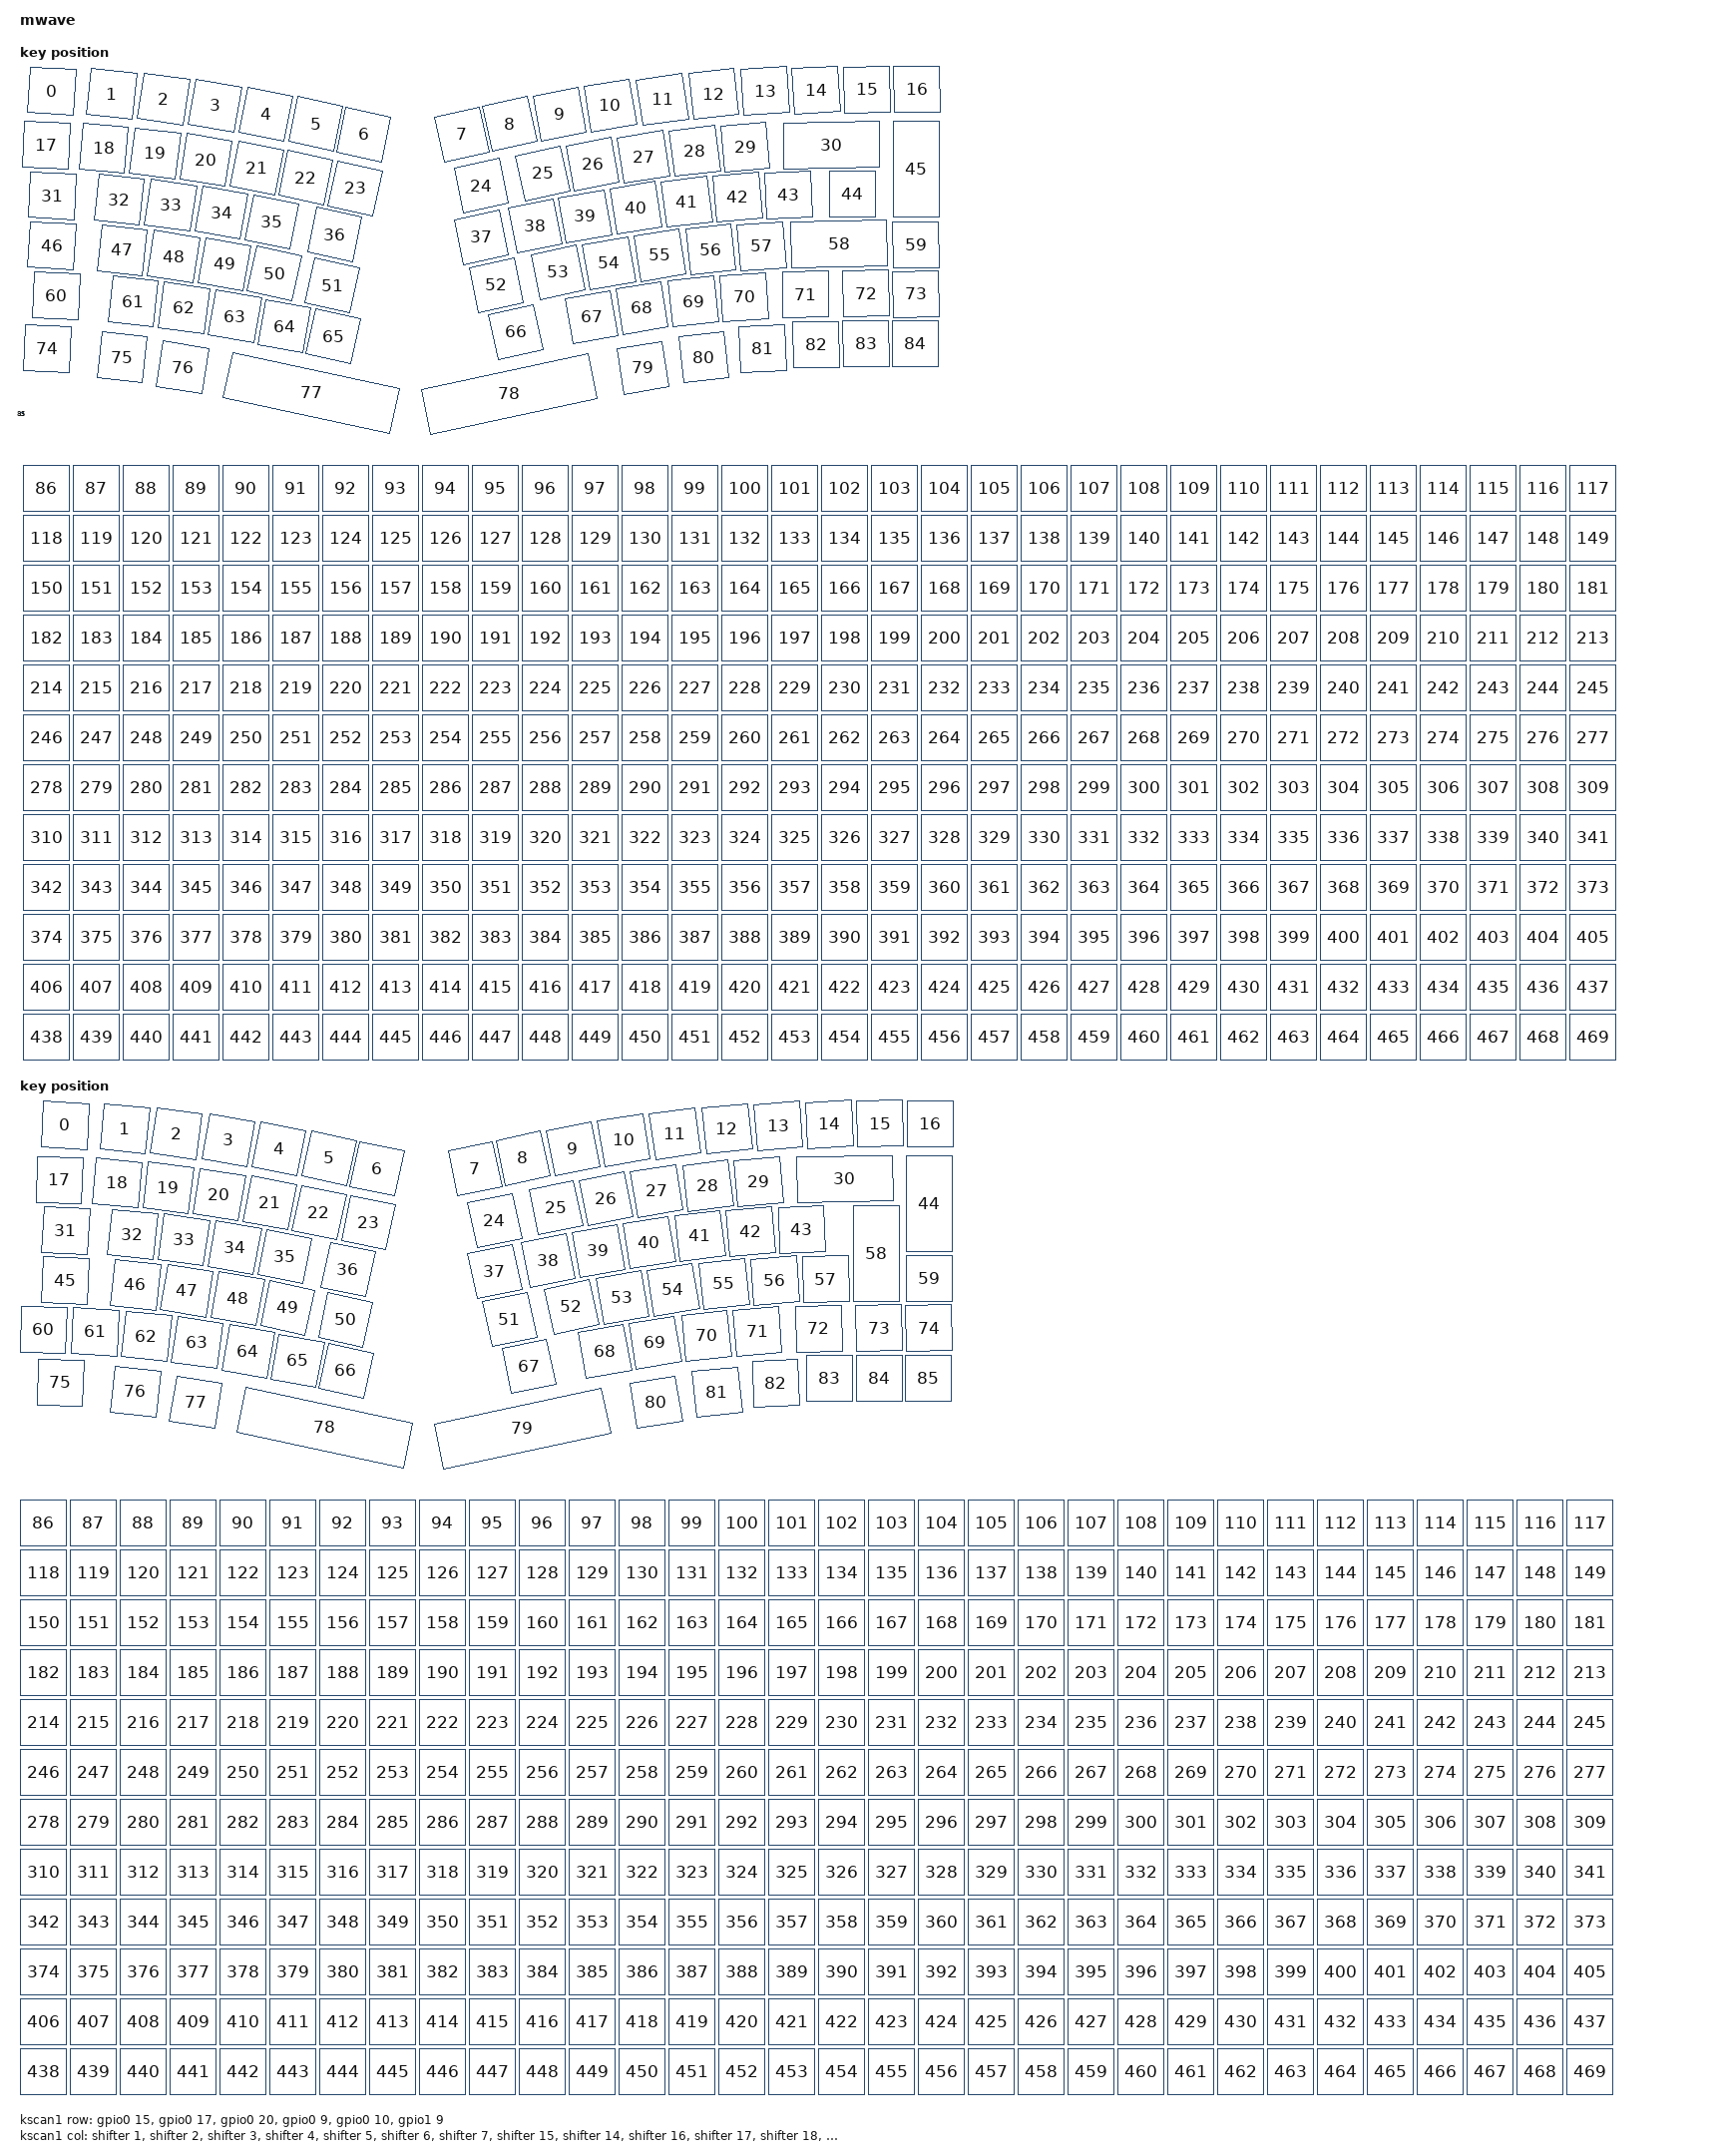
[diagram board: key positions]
/*
 * Copyright (c) 2024 The ZMK Contributors
 *
 * SPDX-License-Identifier: MIT
 */

 /dts-v1/;

 #include "lcp_33.dtsi"
 #include "mwave_transform.dtsi"
 #include <physical_layouts.dtsi>

 / {
    model = "mwave";
    compatible = "kinesis,mwave";

    chosen {
        zmk,physical-layout = &layout_0;
        zmk,indicators = &led_strip_1;
        zmk,caps-led = &ind_leds;
    };

    vbatt: vbatt {
    compatible = "kinesis,battery-voltage-divider";
    io-channels = <&adc 6>;
    output-ohms = <3000000>;
    full-ohms = <(2000000 + 3000000)>;
    chemistry = <ALKALINE>;
    };

    kscan1: kscan_1 {
        compatible = "zmk,kscan-gpio-matrix";
        wakeup-source;

        diode-direction = "col2row";

        col-gpios
            = <&shifter 1 GPIO_ACTIVE_HIGH>
            , <&shifter 2 GPIO_ACTIVE_HIGH>
            , <&shifter 3 GPIO_ACTIVE_HIGH>
            , <&shifter 4 GPIO_ACTIVE_HIGH>
            , <&shifter 5 GPIO_ACTIVE_HIGH>
            , <&shifter 6 GPIO_ACTIVE_HIGH>
            , <&shifter 7 GPIO_ACTIVE_HIGH>
            , <&shifter 15 GPIO_ACTIVE_HIGH>
            , <&shifter 14 GPIO_ACTIVE_HIGH>
            , <&shifter 16 GPIO_ACTIVE_HIGH>
            , <&shifter 17 GPIO_ACTIVE_HIGH>
            , <&shifter 18 GPIO_ACTIVE_HIGH>
            , <&shifter 19 GPIO_ACTIVE_HIGH>
            , <&shifter 20 GPIO_ACTIVE_HIGH>
            , <&shifter 21 GPIO_ACTIVE_HIGH>
            , <&shifter 22 GPIO_ACTIVE_HIGH>
            , <&shifter 23 GPIO_ACTIVE_HIGH>
            ;

        row-gpios
            = <&gpio0 15 (GPIO_ACTIVE_HIGH | GPIO_PULL_DOWN)>
            , <&gpio0 17 (GPIO_ACTIVE_HIGH | GPIO_PULL_DOWN)>
            , <&gpio0 20 (GPIO_ACTIVE_HIGH | GPIO_PULL_DOWN)>
            , <&gpio0 9 (GPIO_ACTIVE_HIGH | GPIO_PULL_DOWN)>
            , <&gpio0 10 (GPIO_ACTIVE_HIGH | GPIO_PULL_DOWN)>
            , <&gpio1 9 (GPIO_ACTIVE_HIGH | GPIO_PULL_DOWN)>
            ;
    };
 
    led_0: led_0 {
        compatible = "gpio-leds";
        red_led: led_0r {
            gpios = <&shifter 11 GPIO_ACTIVE_LOW>;
        };
        green_led: led_0g {
            gpios = <&shifter 12 GPIO_ACTIVE_LOW>;
        };
        blue_led: led_0b {
            gpios = <&shifter 13 GPIO_ACTIVE_LOW>;
        };
    };
 
    led_1: led_1 {
        compatible = "gpio-leds";
        red_led1: led_1r {
            gpios = <&shifter 8 GPIO_ACTIVE_LOW>;
        };
        green_led1: led_1g {
            gpios = <&shifter 9 GPIO_ACTIVE_LOW>;
        };
        blue_led1: led_1b {
            gpios = <&shifter 10 GPIO_ACTIVE_LOW>;
        };
    };

    ind_leds: ind_leds {
        compatible = "gpio-leds";
        capsled: caps_led {
            gpios = <&shifter 0 GPIO_ACTIVE_LOW>;
        };
    };

    led_strip_1: gpio_led_strip {
        compatible = "zmk,gpio-led-strip";
        chain-length = <2>;
        led-0 {
            led = <&led_0>;
        };
        led-1 {
            led = <&led_1>;
        };
    };

    layout_0: layout_0 {
        compatible = "zmk,physical-layout";
        display-name = "ANSI Layout";

        kscan = <&kscan1>;
        transform = <&ansi_transform>;

        keys  //                     w   h    x    y     rot    rx    ry
            = <&key_physical_attrs 100 100   11    3     310    61    53>
            , <&key_physical_attrs 100 100  131    9     610   181    59>
            , <&key_physical_attrs 100 100  235   19     810   285    69>
            , <&key_physical_attrs 100 100  338   32    1010   388    83>
            , <&key_physical_attrs 100 100  440   50    1110   490   100>
            , <&key_physical_attrs 100 100  540   69    1210   590   119>
            , <&key_physical_attrs 100 100  636   90    1210   686   140>
            , <&key_physical_attrs 100 100  833   90 (-1210)   883   140>
            , <&key_physical_attrs 100 100  929   69 (-1210)   979   119>
            , <&key_physical_attrs 100 100 1029   50 (-1110)  1079   100>
            , <&key_physical_attrs 100 100 1131   32  (-910)  1181    83>
            , <&key_physical_attrs 100 100 1235   20  (-810)  1285    70>
            , <&key_physical_attrs 100 100 1338    9  (-610)  1388    59>
            , <&key_physical_attrs 100 100 1441    3  (-409)  1491    53>
            , <&key_physical_attrs 100 100 1543    1  (-310)  1593    51>
            , <&key_physical_attrs 100 100 1645    0  (-110)  1695    50>
            , <&key_physical_attrs 100 100 1745    0   (-10)  1795    50>
            , <&key_physical_attrs 100 100    0  112     210    50   162>
            , <&key_physical_attrs 100 100  115  118     509   165   168>
            , <&key_physical_attrs 100 100  218  128     710   268   178>
            , <&key_physical_attrs 100 100  320  141     910   370   191>
            , <&key_physical_attrs 100 100  422  158    1110   472   208>
            , <&key_physical_attrs 100 100  520  177    1210   570   227>
            , <&key_physical_attrs 100 100  619  198    1210   669   248>
            , <&key_physical_attrs 100 100  872  193 (-1210)   922   243>
            , <&key_physical_attrs 100 100  995  168 (-1210)  1045   218>
            , <&key_physical_attrs 100 100 1095  150 (-1110)  1145   200>
            , <&key_physical_attrs 100 100 1197  135  (-910)  1247   185>
            , <&key_physical_attrs 100 100 1300  123  (-710)  1350   173>
            , <&key_physical_attrs 100 100 1401  115  (-509)  1451   165>
            , <&key_physical_attrs 200 100 1524  111  (-110)  1624   161>
            , <&key_physical_attrs 100 100   12  213     310    62   263>
            , <&key_physical_attrs 100 100  146  221     610   196   271>
            , <&key_physical_attrs 100 100  249  232     810   299   282>
            , <&key_physical_attrs 100 100  351  247    1010   401   297>
            , <&key_physical_attrs 100 100  452  265    1110   502   315>
            , <&key_physical_attrs 100 100  578  291    1210   628   341>
            , <&key_physical_attrs 100 100  872  296 (-1210)   922   346>
            , <&key_physical_attrs 100 100  980  273 (-1110)  1030   323>
            , <&key_physical_attrs 100 100 1080  254 (-1010)  1130   304>
            , <&key_physical_attrs 100 100 1182  237  (-910)  1232   287>
            , <&key_physical_attrs 100 100 1284  225  (-710)  1334   275>
            , <&key_physical_attrs 100 100 1386  216  (-509)  1436   266>
            , <&key_physical_attrs 100 100 1488  212  (-210)  1538   262>
            , <&key_physical_attrs 100 100 1616  210   (-10)  1666   260>
            , <&key_physical_attrs 100 200 1744  110   (-10)  1794   210>
            , <&key_physical_attrs 100 100   11  313     310    61   363>
            , <&key_physical_attrs 100 100  152  322     610   202   372>
            , <&key_physical_attrs 100 100  255  335     910   305   385>
            , <&key_physical_attrs 100 100  357  350    1010   407   400>
            , <&key_physical_attrs 100 100  457  369    1210   507   419>
            , <&key_physical_attrs 100 100  573  393    1210   623   443>
            , <&key_physical_attrs 100 100  902  392 (-1210)   952   442>
            , <&key_physical_attrs 100 100 1026  366 (-1210)  1076   416>
            , <&key_physical_attrs 100 100 1128  348 (-1010)  1178   398>
            , <&key_physical_attrs 100 100 1230  332  (-910)  1280   382>
            , <&key_physical_attrs 100 100 1332  321  (-610)  1382   371>
            , <&key_physical_attrs 100 100 1434  314  (-409)  1484   364>
            , <&key_physical_attrs 200 100 1539  310  (-110)  1639   360>
            , <&key_physical_attrs 100 100 1743  311   (-10)  1793   361>
            , <&key_physical_attrs 100 100   20  414     210    70   464>
            , <&key_physical_attrs 100 100  174  425     610   224   475>
            , <&key_physical_attrs 100 100  276  438     810   326   488>
            , <&key_physical_attrs 100 100  378  455    1010   428   505>
            , <&key_physical_attrs 100 100  477  475    1010   527   525>
            , <&key_physical_attrs 100 100  575  495    1210   625   545>
            , <&key_physical_attrs 100 100  941  486 (-1210)   991   536>
            , <&key_physical_attrs 100 100 1093  456 (-1010)  1143   506>
            , <&key_physical_attrs 100 100 1194  438  (-910)  1244   488>
            , <&key_physical_attrs 100 100 1297  425  (-610)  1347   475>
            , <&key_physical_attrs 100 100 1399  416  (-409)  1449   466>
            , <&key_physical_attrs 100 100 1522  411  (-110)  1572   461>
            , <&key_physical_attrs 100 100 1643  409  (-110)  1693   459>
            , <&key_physical_attrs 100 100 1743  410  (-110)  1793   460>
            , <&key_physical_attrs 100 100    2  519     210    52   569>
            , <&key_physical_attrs 100 100  152  537     610   202   587>
            , <&key_physical_attrs 100 100  273  557     910   323   607>
            , <&key_physical_attrs 350 100  406  612    1210   596   662>
            , <&key_physical_attrs 350 100  803  612 (-1210)   973   662>
            , <&key_physical_attrs 100 100 1196  558  (-910)  1246   608>
            , <&key_physical_attrs 100 100 1318  537  (-610)  1368   587>
            , <&key_physical_attrs 100 100 1436  520  (-210)  1486   570>
            , <&key_physical_attrs 100 100 1543  511   (-10)  1593   561>
            , <&key_physical_attrs 100 100 1643  510   (-10)  1693   560>
            , <&key_physical_attrs 100 100 1742  510   (-10)  1792   560>
            , <&key_physical_attrs 1 1 0  700       0     0     0>
      , <&key_physical_attrs 100 100 0  800       0     0     0>
      , <&key_physical_attrs 100 100 100  800       0     0     0>
      , <&key_physical_attrs 100 100 200  800       0     0     0>
      , <&key_physical_attrs 100 100 300  800       0     0     0>
      , <&key_physical_attrs 100 100 400  800       0     0     0>
      , <&key_physical_attrs 100 100 500  800       0     0     0>
      , <&key_physical_attrs 100 100 600  800       0     0     0>
      , <&key_physical_attrs 100 100 700  800       0     0     0>
      , <&key_physical_attrs 100 100 800  800       0     0     0>
      , <&key_physical_attrs 100 100 900  800       0     0     0>
      , <&key_physical_attrs 100 100 1000  800       0     0     0>
      , <&key_physical_attrs 100 100 1100  800       0     0     0>
      , <&key_physical_attrs 100 100 1200  800       0     0     0>
      , <&key_physical_attrs 100 100 1300  800       0     0     0>
      , <&key_physical_attrs 100 100 1400  800       0     0     0>
      , <&key_physical_attrs 100 100 1500  800       0     0     0>
      , <&key_physical_attrs 100 100 1600  800       0     0     0>
      , <&key_physical_attrs 100 100 1700  800       0     0     0>
      , <&key_physical_attrs 100 100 1800  800       0     0     0>
      , <&key_physical_attrs 100 100 1900  800       0     0     0>
      , <&key_physical_attrs 100 100 2000  800       0     0     0>
      , <&key_physical_attrs 100 100 2100  800       0     0     0>
      , <&key_physical_attrs 100 100 2200  800       0     0     0>
      , <&key_physical_attrs 100 100 2300  800       0     0     0>
      , <&key_physical_attrs 100 100 2400  800       0     0     0>
      , <&key_physical_attrs 100 100 2500  800       0     0     0>
      , <&key_physical_attrs 100 100 2600  800       0     0     0>
      , <&key_physical_attrs 100 100 2700  800       0     0     0>
      , <&key_physical_attrs 100 100 2800  800       0     0     0>
      , <&key_physical_attrs 100 100 2900  800       0     0     0>
      , <&key_physical_attrs 100 100 3000  800       0     0     0>
      , <&key_physical_attrs 100 100 3100  800       0     0     0>
      , <&key_physical_attrs 100 100 0  900       0     0     0>
      , <&key_physical_attrs 100 100 100  900       0     0     0>
      , <&key_physical_attrs 100 100 200  900       0     0     0>
      , <&key_physical_attrs 100 100 300  900       0     0     0>
      , <&key_physical_attrs 100 100 400  900       0     0     0>
      , <&key_physical_attrs 100 100 500  900       0     0     0>
      , <&key_physical_attrs 100 100 600  900       0     0     0>
      , <&key_physical_attrs 100 100 700  900       0     0     0>
      , <&key_physical_attrs 100 100 800  900       0     0     0>
      , <&key_physical_attrs 100 100 900  900       0     0     0>
      , <&key_physical_attrs 100 100 1000  900       0     0     0>
      , <&key_physical_attrs 100 100 1100  900       0     0     0>
      , <&key_physical_attrs 100 100 1200  900       0     0     0>
      , <&key_physical_attrs 100 100 1300  900       0     0     0>
      , <&key_physical_attrs 100 100 1400  900       0     0     0>
      , <&key_physical_attrs 100 100 1500  900       0     0     0>
      , <&key_physical_attrs 100 100 1600  900       0     0     0>
      , <&key_physical_attrs 100 100 1700  900       0     0     0>
      , <&key_physical_attrs 100 100 1800  900       0     0     0>
      , <&key_physical_attrs 100 100 1900  900       0     0     0>
      , <&key_physical_attrs 100 100 2000  900       0     0     0>
      , <&key_physical_attrs 100 100 2100  900       0     0     0>
      , <&key_physical_attrs 100 100 2200  900       0     0     0>
      , <&key_physical_attrs 100 100 2300  900       0     0     0>
      , <&key_physical_attrs 100 100 2400  900       0     0     0>
      , <&key_physical_attrs 100 100 2500  900       0     0     0>
      , <&key_physical_attrs 100 100 2600  900       0     0     0>
      , <&key_physical_attrs 100 100 2700  900       0     0     0>
      , <&key_physical_attrs 100 100 2800  900       0     0     0>
      , <&key_physical_attrs 100 100 2900  900       0     0     0>
      , <&key_physical_attrs 100 100 3000  900       0     0     0>
      , <&key_physical_attrs 100 100 3100  900       0     0     0>
      , <&key_physical_attrs 100 100 0  1000       0     0     0>
      , <&key_physical_attrs 100 100 100  1000       0     0     0>
      , <&key_physical_attrs 100 100 200  1000       0     0     0>
      , <&key_physical_attrs 100 100 300  1000       0     0     0>
      , <&key_physical_attrs 100 100 400  1000       0     0     0>
      , <&key_physical_attrs 100 100 500  1000       0     0     0>
      , <&key_physical_attrs 100 100 600  1000       0     0     0>
      , <&key_physical_attrs 100 100 700  1000       0     0     0>
      , <&key_physical_attrs 100 100 800  1000       0     0     0>
      , <&key_physical_attrs 100 100 900  1000       0     0     0>
      , <&key_physical_attrs 100 100 1000  1000       0     0     0>
      , <&key_physical_attrs 100 100 1100  1000       0     0     0>
      , <&key_physical_attrs 100 100 1200  1000       0     0     0>
      , <&key_physical_attrs 100 100 1300  1000       0     0     0>
      , <&key_physical_attrs 100 100 1400  1000       0     0     0>
      , <&key_physical_attrs 100 100 1500  1000       0     0     0>
      , <&key_physical_attrs 100 100 1600  1000       0     0     0>
      , <&key_physical_attrs 100 100 1700  1000       0     0     0>
      , <&key_physical_attrs 100 100 1800  1000       0     0     0>
      , <&key_physical_attrs 100 100 1900  1000       0     0     0>
      , <&key_physical_attrs 100 100 2000  1000       0     0     0>
      , <&key_physical_attrs 100 100 2100  1000       0     0     0>
      , <&key_physical_attrs 100 100 2200  1000       0     0     0>
      , <&key_physical_attrs 100 100 2300  1000       0     0     0>
      , <&key_physical_attrs 100 100 2400  1000       0     0     0>
      , <&key_physical_attrs 100 100 2500  1000       0     0     0>
      , <&key_physical_attrs 100 100 2600  1000       0     0     0>
      , <&key_physical_attrs 100 100 2700  1000       0     0     0>
      , <&key_physical_attrs 100 100 2800  1000       0     0     0>
      , <&key_physical_attrs 100 100 2900  1000       0     0     0>
      , <&key_physical_attrs 100 100 3000  1000       0     0     0>
      , <&key_physical_attrs 100 100 3100  1000       0     0     0>
      , <&key_physical_attrs 100 100 0  1100       0     0     0>
      , <&key_physical_attrs 100 100 100  1100       0     0     0>
      , <&key_physical_attrs 100 100 200  1100       0     0     0>
      , <&key_physical_attrs 100 100 300  1100       0     0     0>
      , <&key_physical_attrs 100 100 400  1100       0     0     0>
      , <&key_physical_attrs 100 100 500  1100       0     0     0>
      , <&key_physical_attrs 100 100 600  1100       0     0     0>
      , <&key_physical_attrs 100 100 700  1100       0     0     0>
      , <&key_physical_attrs 100 100 800  1100       0     0     0>
      , <&key_physical_attrs 100 100 900  1100       0     0     0>
      , <&key_physical_attrs 100 100 1000  1100       0     0     0>
      , <&key_physical_attrs 100 100 1100  1100       0     0     0>
      , <&key_physical_attrs 100 100 1200  1100       0     0     0>
      , <&key_physical_attrs 100 100 1300  1100       0     0     0>
      , <&key_physical_attrs 100 100 1400  1100       0     0     0>
      , <&key_physical_attrs 100 100 1500  1100       0     0     0>
      , <&key_physical_attrs 100 100 1600  1100       0     0     0>
      , <&key_physical_attrs 100 100 1700  1100       0     0     0>
      , <&key_physical_attrs 100 100 1800  1100       0     0     0>
      , <&key_physical_attrs 100 100 1900  1100       0     0     0>
      , <&key_physical_attrs 100 100 2000  1100       0     0     0>
      , <&key_physical_attrs 100 100 2100  1100       0     0     0>
      , <&key_physical_attrs 100 100 2200  1100       0     0     0>
      , <&key_physical_attrs 100 100 2300  1100       0     0     0>
      , <&key_physical_attrs 100 100 2400  1100       0     0     0>
      , <&key_physical_attrs 100 100 2500  1100       0     0     0>
      , <&key_physical_attrs 100 100 2600  1100       0     0     0>
      , <&key_physical_attrs 100 100 2700  1100       0     0     0>
      , <&key_physical_attrs 100 100 2800  1100       0     0     0>
      , <&key_physical_attrs 100 100 2900  1100       0     0     0>
      , <&key_physical_attrs 100 100 3000  1100       0     0     0>
      , <&key_physical_attrs 100 100 3100  1100       0     0     0>
      , <&key_physical_attrs 100 100 0  1200       0     0     0>
      , <&key_physical_attrs 100 100 100  1200       0     0     0>
      , <&key_physical_attrs 100 100 200  1200       0     0     0>
      , <&key_physical_attrs 100 100 300  1200       0     0     0>
      , <&key_physical_attrs 100 100 400  1200       0     0     0>
      , <&key_physical_attrs 100 100 500  1200       0     0     0>
      , <&key_physical_attrs 100 100 600  1200       0     0     0>
      , <&key_physical_attrs 100 100 700  1200       0     0     0>
      , <&key_physical_attrs 100 100 800  1200       0     0     0>
      , <&key_physical_attrs 100 100 900  1200       0     0     0>
      , <&key_physical_attrs 100 100 1000  1200       0     0     0>
      , <&key_physical_attrs 100 100 1100  1200       0     0     0>
      , <&key_physical_attrs 100 100 1200  1200       0     0     0>
      , <&key_physical_attrs 100 100 1300  1200       0     0     0>
      , <&key_physical_attrs 100 100 1400  1200       0     0     0>
      , <&key_physical_attrs 100 100 1500  1200       0     0     0>
      , <&key_physical_attrs 100 100 1600  1200       0     0     0>
      , <&key_physical_attrs 100 100 1700  1200       0     0     0>
      , <&key_physical_attrs 100 100 1800  1200       0     0     0>
      , <&key_physical_attrs 100 100 1900  1200       0     0     0>
      , <&key_physical_attrs 100 100 2000  1200       0     0     0>
      , <&key_physical_attrs 100 100 2100  1200       0     0     0>
      , <&key_physical_attrs 100 100 2200  1200       0     0     0>
      , <&key_physical_attrs 100 100 2300  1200       0     0     0>
      , <&key_physical_attrs 100 100 2400  1200       0     0     0>
      , <&key_physical_attrs 100 100 2500  1200       0     0     0>
      , <&key_physical_attrs 100 100 2600  1200       0     0     0>
      , <&key_physical_attrs 100 100 2700  1200       0     0     0>
      , <&key_physical_attrs 100 100 2800  1200       0     0     0>
      , <&key_physical_attrs 100 100 2900  1200       0     0     0>
      , <&key_physical_attrs 100 100 3000  1200       0     0     0>
      , <&key_physical_attrs 100 100 3100  1200       0     0     0>
      , <&key_physical_attrs 100 100 0  1300       0     0     0>
      , <&key_physical_attrs 100 100 100  1300       0     0     0>
      , <&key_physical_attrs 100 100 200  1300       0     0     0>
      , <&key_physical_attrs 100 100 300  1300       0     0     0>
      , <&key_physical_attrs 100 100 400  1300       0     0     0>
      , <&key_physical_attrs 100 100 500  1300       0     0     0>
      , <&key_physical_attrs 100 100 600  1300       0     0     0>
      , <&key_physical_attrs 100 100 700  1300       0     0     0>
      , <&key_physical_attrs 100 100 800  1300       0     0     0>
      , <&key_physical_attrs 100 100 900  1300       0     0     0>
      , <&key_physical_attrs 100 100 1000  1300       0     0     0>
      , <&key_physical_attrs 100 100 1100  1300       0     0     0>
      , <&key_physical_attrs 100 100 1200  1300       0     0     0>
      , <&key_physical_attrs 100 100 1300  1300       0     0     0>
      , <&key_physical_attrs 100 100 1400  1300       0     0     0>
      , <&key_physical_attrs 100 100 1500  1300       0     0     0>
      , <&key_physical_attrs 100 100 1600  1300       0     0     0>
      , <&key_physical_attrs 100 100 1700  1300       0     0     0>
      , <&key_physical_attrs 100 100 1800  1300       0     0     0>
      , <&key_physical_attrs 100 100 1900  1300       0     0     0>
      , <&key_physical_attrs 100 100 2000  1300       0     0     0>
      , <&key_physical_attrs 100 100 2100  1300       0     0     0>
      , <&key_physical_attrs 100 100 2200  1300       0     0     0>
      , <&key_physical_attrs 100 100 2300  1300       0     0     0>
      , <&key_physical_attrs 100 100 2400  1300       0     0     0>
      , <&key_physical_attrs 100 100 2500  1300       0     0     0>
      , <&key_physical_attrs 100 100 2600  1300       0     0     0>
      , <&key_physical_attrs 100 100 2700  1300       0     0     0>
      , <&key_physical_attrs 100 100 2800  1300       0     0     0>
      , <&key_physical_attrs 100 100 2900  1300       0     0     0>
      , <&key_physical_attrs 100 100 3000  1300       0     0     0>
      , <&key_physical_attrs 100 100 3100  1300       0     0     0>
      , <&key_physical_attrs 100 100 0  1400       0     0     0>
      , <&key_physical_attrs 100 100 100  1400       0     0     0>
      , <&key_physical_attrs 100 100 200  1400       0     0     0>
      , <&key_physical_attrs 100 100 300  1400       0     0     0>
      , <&key_physical_attrs 100 100 400  1400       0     0     0>
      , <&key_physical_attrs 100 100 500  1400       0     0     0>
      , <&key_physical_attrs 100 100 600  1400       0     0     0>
      , <&key_physical_attrs 100 100 700  1400       0     0     0>
      , <&key_physical_attrs 100 100 800  1400       0     0     0>
      , <&key_physical_attrs 100 100 900  1400       0     0     0>
      , <&key_physical_attrs 100 100 1000  1400       0     0     0>
      , <&key_physical_attrs 100 100 1100  1400       0     0     0>
      , <&key_physical_attrs 100 100 1200  1400       0     0     0>
      , <&key_physical_attrs 100 100 1300  1400       0     0     0>
      , <&key_physical_attrs 100 100 1400  1400       0     0     0>
      , <&key_physical_attrs 100 100 1500  1400       0     0     0>
      , <&key_physical_attrs 100 100 1600  1400       0     0     0>
      , <&key_physical_attrs 100 100 1700  1400       0     0     0>
      , <&key_physical_attrs 100 100 1800  1400       0     0     0>
      , <&key_physical_attrs 100 100 1900  1400       0     0     0>
      , <&key_physical_attrs 100 100 2000  1400       0     0     0>
      , <&key_physical_attrs 100 100 2100  1400       0     0     0>
      , <&key_physical_attrs 100 100 2200  1400       0     0     0>
      , <&key_physical_attrs 100 100 2300  1400       0     0     0>
      , <&key_physical_attrs 100 100 2400  1400       0     0     0>
      , <&key_physical_attrs 100 100 2500  1400       0     0     0>
      , <&key_physical_attrs 100 100 2600  1400       0     0     0>
      , <&key_physical_attrs 100 100 2700  1400       0     0     0>
      , <&key_physical_attrs 100 100 2800  1400       0     0     0>
      , <&key_physical_attrs 100 100 2900  1400       0     0     0>
      , <&key_physical_attrs 100 100 3000  1400       0     0     0>
      , <&key_physical_attrs 100 100 3100  1400       0     0     0>
      , <&key_physical_attrs 100 100 0  1500       0     0     0>
      , <&key_physical_attrs 100 100 100  1500       0     0     0>
      , <&key_physical_attrs 100 100 200  1500       0     0     0>
      , <&key_physical_attrs 100 100 300  1500       0     0     0>
      , <&key_physical_attrs 100 100 400  1500       0     0     0>
      , <&key_physical_attrs 100 100 500  1500       0     0     0>
      , <&key_physical_attrs 100 100 600  1500       0     0     0>
      , <&key_physical_attrs 100 100 700  1500       0     0     0>
      , <&key_physical_attrs 100 100 800  1500       0     0     0>
      , <&key_physical_attrs 100 100 900  1500       0     0     0>
      , <&key_physical_attrs 100 100 1000  1500       0     0     0>
      , <&key_physical_attrs 100 100 1100  1500       0     0     0>
      , <&key_physical_attrs 100 100 1200  1500       0     0     0>
      , <&key_physical_attrs 100 100 1300  1500       0     0     0>
      , <&key_physical_attrs 100 100 1400  1500       0     0     0>
      , <&key_physical_attrs 100 100 1500  1500       0     0     0>
      , <&key_physical_attrs 100 100 1600  1500       0     0     0>
      , <&key_physical_attrs 100 100 1700  1500       0     0     0>
      , <&key_physical_attrs 100 100 1800  1500       0     0     0>
      , <&key_physical_attrs 100 100 1900  1500       0     0     0>
      , <&key_physical_attrs 100 100 2000  1500       0     0     0>
      , <&key_physical_attrs 100 100 2100  1500       0     0     0>
      , <&key_physical_attrs 100 100 2200  1500       0     0     0>
      , <&key_physical_attrs 100 100 2300  1500       0     0     0>
      , <&key_physical_attrs 100 100 2400  1500       0     0     0>
      , <&key_physical_attrs 100 100 2500  1500       0     0     0>
      , <&key_physical_attrs 100 100 2600  1500       0     0     0>
      , <&key_physical_attrs 100 100 2700  1500       0     0     0>
      , <&key_physical_attrs 100 100 2800  1500       0     0     0>
      , <&key_physical_attrs 100 100 2900  1500       0     0     0>
      , <&key_physical_attrs 100 100 3000  1500       0     0     0>
      , <&key_physical_attrs 100 100 3100  1500       0     0     0>
      , <&key_physical_attrs 100 100 0  1600       0     0     0>
      , <&key_physical_attrs 100 100 100  1600       0     0     0>
      , <&key_physical_attrs 100 100 200  1600       0     0     0>
      , <&key_physical_attrs 100 100 300  1600       0     0     0>
      , <&key_physical_attrs 100 100 400  1600       0     0     0>
      , <&key_physical_attrs 100 100 500  1600       0     0     0>
      , <&key_physical_attrs 100 100 600  1600       0     0     0>
      , <&key_physical_attrs 100 100 700  1600       0     0     0>
      , <&key_physical_attrs 100 100 800  1600       0     0     0>
      , <&key_physical_attrs 100 100 900  1600       0     0     0>
      , <&key_physical_attrs 100 100 1000  1600       0     0     0>
      , <&key_physical_attrs 100 100 1100  1600       0     0     0>
      , <&key_physical_attrs 100 100 1200  1600       0     0     0>
      , <&key_physical_attrs 100 100 1300  1600       0     0     0>
      , <&key_physical_attrs 100 100 1400  1600       0     0     0>
      , <&key_physical_attrs 100 100 1500  1600       0     0     0>
      , <&key_physical_attrs 100 100 1600  1600       0     0     0>
      , <&key_physical_attrs 100 100 1700  1600       0     0     0>
      , <&key_physical_attrs 100 100 1800  1600       0     0     0>
      , <&key_physical_attrs 100 100 1900  1600       0     0     0>
      , <&key_physical_attrs 100 100 2000  1600       0     0     0>
      , <&key_physical_attrs 100 100 2100  1600       0     0     0>
      , <&key_physical_attrs 100 100 2200  1600       0     0     0>
      , <&key_physical_attrs 100 100 2300  1600       0     0     0>
      , <&key_physical_attrs 100 100 2400  1600       0     0     0>
      , <&key_physical_attrs 100 100 2500  1600       0     0     0>
      , <&key_physical_attrs 100 100 2600  1600       0     0     0>
      , <&key_physical_attrs 100 100 2700  1600       0     0     0>
      , <&key_physical_attrs 100 100 2800  1600       0     0     0>
      , <&key_physical_attrs 100 100 2900  1600       0     0     0>
      , <&key_physical_attrs 100 100 3000  1600       0     0     0>
      , <&key_physical_attrs 100 100 3100  1600       0     0     0>
      , <&key_physical_attrs 100 100 0  1700       0     0     0>
      , <&key_physical_attrs 100 100 100  1700       0     0     0>
      , <&key_physical_attrs 100 100 200  1700       0     0     0>
      , <&key_physical_attrs 100 100 300  1700       0     0     0>
      , <&key_physical_attrs 100 100 400  1700       0     0     0>
      , <&key_physical_attrs 100 100 500  1700       0     0     0>
      , <&key_physical_attrs 100 100 600  1700       0     0     0>
      , <&key_physical_attrs 100 100 700  1700       0     0     0>
      , <&key_physical_attrs 100 100 800  1700       0     0     0>
      , <&key_physical_attrs 100 100 900  1700       0     0     0>
      , <&key_physical_attrs 100 100 1000  1700       0     0     0>
      , <&key_physical_attrs 100 100 1100  1700       0     0     0>
      , <&key_physical_attrs 100 100 1200  1700       0     0     0>
      , <&key_physical_attrs 100 100 1300  1700       0     0     0>
      , <&key_physical_attrs 100 100 1400  1700       0     0     0>
      , <&key_physical_attrs 100 100 1500  1700       0     0     0>
      , <&key_physical_attrs 100 100 1600  1700       0     0     0>
      , <&key_physical_attrs 100 100 1700  1700       0     0     0>
      , <&key_physical_attrs 100 100 1800  1700       0     0     0>
      , <&key_physical_attrs 100 100 1900  1700       0     0     0>
      , <&key_physical_attrs 100 100 2000  1700       0     0     0>
      , <&key_physical_attrs 100 100 2100  1700       0     0     0>
      , <&key_physical_attrs 100 100 2200  1700       0     0     0>
      , <&key_physical_attrs 100 100 2300  1700       0     0     0>
      , <&key_physical_attrs 100 100 2400  1700       0     0     0>
      , <&key_physical_attrs 100 100 2500  1700       0     0     0>
      , <&key_physical_attrs 100 100 2600  1700       0     0     0>
      , <&key_physical_attrs 100 100 2700  1700       0     0     0>
      , <&key_physical_attrs 100 100 2800  1700       0     0     0>
      , <&key_physical_attrs 100 100 2900  1700       0     0     0>
      , <&key_physical_attrs 100 100 3000  1700       0     0     0>
      , <&key_physical_attrs 100 100 3100  1700       0     0     0>
      , <&key_physical_attrs 100 100 0  1800       0     0     0>
      , <&key_physical_attrs 100 100 100  1800       0     0     0>
      , <&key_physical_attrs 100 100 200  1800       0     0     0>
      , <&key_physical_attrs 100 100 300  1800       0     0     0>
      , <&key_physical_attrs 100 100 400  1800       0     0     0>
      , <&key_physical_attrs 100 100 500  1800       0     0     0>
      , <&key_physical_attrs 100 100 600  1800       0     0     0>
      , <&key_physical_attrs 100 100 700  1800       0     0     0>
      , <&key_physical_attrs 100 100 800  1800       0     0     0>
      , <&key_physical_attrs 100 100 900  1800       0     0     0>
      , <&key_physical_attrs 100 100 1000  1800       0     0     0>
      , <&key_physical_attrs 100 100 1100  1800       0     0     0>
      , <&key_physical_attrs 100 100 1200  1800       0     0     0>
      , <&key_physical_attrs 100 100 1300  1800       0     0     0>
      , <&key_physical_attrs 100 100 1400  1800       0     0     0>
      , <&key_physical_attrs 100 100 1500  1800       0     0     0>
      , <&key_physical_attrs 100 100 1600  1800       0     0     0>
      , <&key_physical_attrs 100 100 1700  1800       0     0     0>
      , <&key_physical_attrs 100 100 1800  1800       0     0     0>
      , <&key_physical_attrs 100 100 1900  1800       0     0     0>
      , <&key_physical_attrs 100 100 2000  1800       0     0     0>
      , <&key_physical_attrs 100 100 2100  1800       0     0     0>
      , <&key_physical_attrs 100 100 2200  1800       0     0     0>
      , <&key_physical_attrs 100 100 2300  1800       0     0     0>
      , <&key_physical_attrs 100 100 2400  1800       0     0     0>
      , <&key_physical_attrs 100 100 2500  1800       0     0     0>
      , <&key_physical_attrs 100 100 2600  1800       0     0     0>
      , <&key_physical_attrs 100 100 2700  1800       0     0     0>
      , <&key_physical_attrs 100 100 2800  1800       0     0     0>
      , <&key_physical_attrs 100 100 2900  1800       0     0     0>
      , <&key_physical_attrs 100 100 3000  1800       0     0     0>
      , <&key_physical_attrs 100 100 3100  1800       0     0     0>
      , <&key_physical_attrs 100 100 0  1900       0     0     0>
      , <&key_physical_attrs 100 100 100  1900       0     0     0>
      , <&key_physical_attrs 100 100 200  1900       0     0     0>
      , <&key_physical_attrs 100 100 300  1900       0     0     0>
      , <&key_physical_attrs 100 100 400  1900       0     0     0>
      , <&key_physical_attrs 100 100 500  1900       0     0     0>
      , <&key_physical_attrs 100 100 600  1900       0     0     0>
      , <&key_physical_attrs 100 100 700  1900       0     0     0>
      , <&key_physical_attrs 100 100 800  1900       0     0     0>
      , <&key_physical_attrs 100 100 900  1900       0     0     0>
      , <&key_physical_attrs 100 100 1000  1900       0     0     0>
      , <&key_physical_attrs 100 100 1100  1900       0     0     0>
      , <&key_physical_attrs 100 100 1200  1900       0     0     0>
      , <&key_physical_attrs 100 100 1300  1900       0     0     0>
      , <&key_physical_attrs 100 100 1400  1900       0     0     0>
      , <&key_physical_attrs 100 100 1500  1900       0     0     0>
      , <&key_physical_attrs 100 100 1600  1900       0     0     0>
      , <&key_physical_attrs 100 100 1700  1900       0     0     0>
      , <&key_physical_attrs 100 100 1800  1900       0     0     0>
      , <&key_physical_attrs 100 100 1900  1900       0     0     0>
      , <&key_physical_attrs 100 100 2000  1900       0     0     0>
      , <&key_physical_attrs 100 100 2100  1900       0     0     0>
      , <&key_physical_attrs 100 100 2200  1900       0     0     0>
      , <&key_physical_attrs 100 100 2300  1900       0     0     0>
      , <&key_physical_attrs 100 100 2400  1900       0     0     0>
      , <&key_physical_attrs 100 100 2500  1900       0     0     0>
      , <&key_physical_attrs 100 100 2600  1900       0     0     0>
      , <&key_physical_attrs 100 100 2700  1900       0     0     0>
      , <&key_physical_attrs 100 100 2800  1900       0     0     0>
      , <&key_physical_attrs 100 100 2900  1900       0     0     0>
      , <&key_physical_attrs 100 100 3000  1900       0     0     0>
      , <&key_physical_attrs 100 100 3100  1900       0     0     0>
            ;
    };

    layout_1: layout_1 {
        compatible = "zmk,physical-layout";
        display-name = "ISO Layout";

        kscan = <&kscan1>;
        transform = <&iso_transform>;

        keys  //                     w   h    x    y     rot    rx    ry
            = <&key_physical_attrs 100 100   43    3     310    93    53>
            , <&key_physical_attrs 100 100  163   10     610   213    60>
            , <&key_physical_attrs 100 100  266   20     810   316    70>
            , <&key_physical_attrs 100 100  370   33    1010   420    83>
            , <&key_physical_attrs 100 100  472   50    1110   522   100>
            , <&key_physical_attrs 100 100  572   69    1210   622   119>
            , <&key_physical_attrs 100 100  668   90    1210   718   140>
            , <&key_physical_attrs 100 100  865   90 (-1210)   915   140>
            , <&key_physical_attrs 100 100  961   69 (-1210)  1011   119>
            , <&key_physical_attrs 100 100 1061   50 (-1110)  1111   100>
            , <&key_physical_attrs 100 100 1163   33  (-910)  1213    83>
            , <&key_physical_attrs 100 100 1266   20  (-810)  1316    70>
            , <&key_physical_attrs 100 100 1370   10  (-610)  1420    60>
            , <&key_physical_attrs 100 100 1473    4  (-410)  1523    54>
            , <&key_physical_attrs 100 100 1575    1  (-310)  1625    51>
            , <&key_physical_attrs 100 100 1677    0  (-110)  1727    50>
            , <&key_physical_attrs 100 100 1777    0   (-10)  1827    50>
            , <&key_physical_attrs 100 100   32  113     210    82   163>
            , <&key_physical_attrs 100 100  148  119     510   198   169>
            , <&key_physical_attrs 100 100  250  128     710   300   178>
            , <&key_physical_attrs 100 100  352  142     910   402   192>
            , <&key_physical_attrs 100 100  454  159    1110   504   209>
            , <&key_physical_attrs 100 100  552  178    1210   602   228>
            , <&key_physical_attrs 100 100  651  198    1210   701   248>
            , <&key_physical_attrs 100 100  904  194 (-1210)   954   244>
            , <&key_physical_attrs 100 100 1027  168 (-1210)  1077   218>
            , <&key_physical_attrs 100 100 1127  150 (-1110)  1177   200>
            , <&key_physical_attrs 100 100 1229  135  (-910)  1279   185>
            , <&key_physical_attrs 100 100 1332  124  (-710)  1382   174>
            , <&key_physical_attrs 100 100 1433  116  (-510)  1483   166>
            , <&key_physical_attrs 200 100 1556  111  (-110)  1656   161>
            , <&key_physical_attrs 100 100   44  214     310    94   264>
            , <&key_physical_attrs 100 100  178  222     610   228   272>
            , <&key_physical_attrs 100 100  281  233     810   331   283>
            , <&key_physical_attrs 100 100  383  248    1010   433   298>
            , <&key_physical_attrs 100 100  484  266    1110   534   316>
            , <&key_physical_attrs 100 100  610  292    1210   660   342>
            , <&key_physical_attrs 100 100  904  296 (-1210)   954   346>
            , <&key_physical_attrs 100 100 1012  274 (-1110)  1062   324>
            , <&key_physical_attrs 100 100 1112  255 (-1010)  1162   305>
            , <&key_physical_attrs 100 100 1214  238  (-910)  1264   288>
            , <&key_physical_attrs 100 100 1316  225  (-710)  1366   275>
            , <&key_physical_attrs 100 100 1418  216  (-510)  1468   266>
            , <&key_physical_attrs 100 100 1520  212  (-210)  1570   262>
            , <&key_physical_attrs 100 200 1776  111   (-10)  1826   211>
            , <&key_physical_attrs 100 100   43  314     310    93   364>
            , <&key_physical_attrs 100 100  184  323     610   234   373>
            , <&key_physical_attrs 100 100  287  335     910   337   385>
            , <&key_physical_attrs 100 100  389  350    1010   439   400>
            , <&key_physical_attrs 100 100  489  369    1210   539   419>
            , <&key_physical_attrs 100 100  605  393    1210   655   443>
            , <&key_physical_attrs 100 100  934  392 (-1210)   984   442>
            , <&key_physical_attrs 100 100 1058  367 (-1210)  1108   417>
            , <&key_physical_attrs 100 100 1160  348 (-1010)  1210   398>
            , <&key_physical_attrs 100 100 1262  333  (-910)  1312   383>
            , <&key_physical_attrs 100 100 1364  321  (-610)  1414   371>
            , <&key_physical_attrs 100 100 1466  314  (-410)  1516   364>
            , <&key_physical_attrs 100 100 1568  312  (-110)  1618   362>
            , <&key_physical_attrs 100 200 1670  211   (-10)  1720   311>
            , <&key_physical_attrs 100 100 1775  311   (-10)  1825   361>
            , <&key_physical_attrs 100 100    0  413     210    50   463>
            , <&key_physical_attrs 100 100  103  417     300   153   467>
            , <&key_physical_attrs 100 100  206  426     610   256   476>
            , <&key_physical_attrs 100 100  308  439     810   358   489>
            , <&key_physical_attrs 100 100  410  456    1010   460   506>
            , <&key_physical_attrs 100 100  509  475    1010   559   525>
            , <&key_physical_attrs 100 100  606  495    1210   656   545>
            , <&key_physical_attrs 100 100  973  486 (-1210)  1023   536>
            , <&key_physical_attrs 100 100 1125  456 (-1010)  1175   506>
            , <&key_physical_attrs 100 100 1226  439  (-910)  1276   489>
            , <&key_physical_attrs 100 100 1329  425  (-610)  1379   475>
            , <&key_physical_attrs 100 100 1431  416  (-410)  1481   466>
            , <&key_physical_attrs 100 100 1554  411  (-110)  1604   461>
            , <&key_physical_attrs 100 100 1675  410  (-110)  1725   460>
            , <&key_physical_attrs 100 100 1775  410  (-110)  1825   460>
            , <&key_physical_attrs 100 100   34  519     210    84   569>
            , <&key_physical_attrs 100 100  184  537     610   234   587>
            , <&key_physical_attrs 100 100  305  558     910   355   608>
            , <&key_physical_attrs 350 100  438  612    1210   628   662>
            , <&key_physical_attrs 350 100  835  612 (-1210)  1005   662>
            , <&key_physical_attrs 100 100 1228  558  (-910)  1278   608>
            , <&key_physical_attrs 100 100 1350  538  (-610)  1400   588>
            , <&key_physical_attrs 100 100 1468  520  (-210)  1518   570>
            , <&key_physical_attrs 100 100 1575  511   (-10)  1625   561>
            , <&key_physical_attrs 100 100 1675  510   (-10)  1725   560>
            , <&key_physical_attrs 100 100 1774  510   (-10)  1824   560>
      , <&key_physical_attrs 100 100 0  800       0     0     0>
      , <&key_physical_attrs 100 100 100  800       0     0     0>
      , <&key_physical_attrs 100 100 200  800       0     0     0>
      , <&key_physical_attrs 100 100 300  800       0     0     0>
      , <&key_physical_attrs 100 100 400  800       0     0     0>
      , <&key_physical_attrs 100 100 500  800       0     0     0>
      , <&key_physical_attrs 100 100 600  800       0     0     0>
      , <&key_physical_attrs 100 100 700  800       0     0     0>
      , <&key_physical_attrs 100 100 800  800       0     0     0>
      , <&key_physical_attrs 100 100 900  800       0     0     0>
      , <&key_physical_attrs 100 100 1000  800       0     0     0>
      , <&key_physical_attrs 100 100 1100  800       0     0     0>
      , <&key_physical_attrs 100 100 1200  800       0     0     0>
      , <&key_physical_attrs 100 100 1300  800       0     0     0>
      , <&key_physical_attrs 100 100 1400  800       0     0     0>
      , <&key_physical_attrs 100 100 1500  800       0     0     0>
      , <&key_physical_attrs 100 100 1600  800       0     0     0>
      , <&key_physical_attrs 100 100 1700  800       0     0     0>
      , <&key_physical_attrs 100 100 1800  800       0     0     0>
      , <&key_physical_attrs 100 100 1900  800       0     0     0>
      , <&key_physical_attrs 100 100 2000  800       0     0     0>
      , <&key_physical_attrs 100 100 2100  800       0     0     0>
      , <&key_physical_attrs 100 100 2200  800       0     0     0>
      , <&key_physical_attrs 100 100 2300  800       0     0     0>
      , <&key_physical_attrs 100 100 2400  800       0     0     0>
      , <&key_physical_attrs 100 100 2500  800       0     0     0>
      , <&key_physical_attrs 100 100 2600  800       0     0     0>
      , <&key_physical_attrs 100 100 2700  800       0     0     0>
      , <&key_physical_attrs 100 100 2800  800       0     0     0>
      , <&key_physical_attrs 100 100 2900  800       0     0     0>
      , <&key_physical_attrs 100 100 3000  800       0     0     0>
      , <&key_physical_attrs 100 100 3100  800       0     0     0>
      , <&key_physical_attrs 100 100 0  900       0     0     0>
      , <&key_physical_attrs 100 100 100  900       0     0     0>
      , <&key_physical_attrs 100 100 200  900       0     0     0>
      , <&key_physical_attrs 100 100 300  900       0     0     0>
      , <&key_physical_attrs 100 100 400  900       0     0     0>
      , <&key_physical_attrs 100 100 500  900       0     0     0>
      , <&key_physical_attrs 100 100 600  900       0     0     0>
      , <&key_physical_attrs 100 100 700  900       0     0     0>
      , <&key_physical_attrs 100 100 800  900       0     0     0>
      , <&key_physical_attrs 100 100 900  900       0     0     0>
      , <&key_physical_attrs 100 100 1000  900       0     0     0>
      , <&key_physical_attrs 100 100 1100  900       0     0     0>
      , <&key_physical_attrs 100 100 1200  900       0     0     0>
      , <&key_physical_attrs 100 100 1300  900       0     0     0>
      , <&key_physical_attrs 100 100 1400  900       0     0     0>
      , <&key_physical_attrs 100 100 1500  900       0     0     0>
      , <&key_physical_attrs 100 100 1600  900       0     0     0>
      , <&key_physical_attrs 100 100 1700  900       0     0     0>
      , <&key_physical_attrs 100 100 1800  900       0     0     0>
      , <&key_physical_attrs 100 100 1900  900       0     0     0>
      , <&key_physical_attrs 100 100 2000  900       0     0     0>
      , <&key_physical_attrs 100 100 2100  900       0     0     0>
      , <&key_physical_attrs 100 100 2200  900       0     0     0>
      , <&key_physical_attrs 100 100 2300  900       0     0     0>
      , <&key_physical_attrs 100 100 2400  900       0     0     0>
      , <&key_physical_attrs 100 100 2500  900       0     0     0>
      , <&key_physical_attrs 100 100 2600  900       0     0     0>
      , <&key_physical_attrs 100 100 2700  900       0     0     0>
      , <&key_physical_attrs 100 100 2800  900       0     0     0>
      , <&key_physical_attrs 100 100 2900  900       0     0     0>
      , <&key_physical_attrs 100 100 3000  900       0     0     0>
      , <&key_physical_attrs 100 100 3100  900       0     0     0>
      , <&key_physical_attrs 100 100 0  1000       0     0     0>
      , <&key_physical_attrs 100 100 100  1000       0     0     0>
      , <&key_physical_attrs 100 100 200  1000       0     0     0>
      , <&key_physical_attrs 100 100 300  1000       0     0     0>
      , <&key_physical_attrs 100 100 400  1000       0     0     0>
      , <&key_physical_attrs 100 100 500  1000       0     0     0>
      , <&key_physical_attrs 100 100 600  1000       0     0     0>
      , <&key_physical_attrs 100 100 700  1000       0     0     0>
      , <&key_physical_attrs 100 100 800  1000       0     0     0>
      , <&key_physical_attrs 100 100 900  1000       0     0     0>
      , <&key_physical_attrs 100 100 1000  1000       0     0     0>
      , <&key_physical_attrs 100 100 1100  1000       0     0     0>
      , <&key_physical_attrs 100 100 1200  1000       0     0     0>
      , <&key_physical_attrs 100 100 1300  1000       0     0     0>
      , <&key_physical_attrs 100 100 1400  1000       0     0     0>
      , <&key_physical_attrs 100 100 1500  1000       0     0     0>
      , <&key_physical_attrs 100 100 1600  1000       0     0     0>
      , <&key_physical_attrs 100 100 1700  1000       0     0     0>
      , <&key_physical_attrs 100 100 1800  1000       0     0     0>
      , <&key_physical_attrs 100 100 1900  1000       0     0     0>
      , <&key_physical_attrs 100 100 2000  1000       0     0     0>
      , <&key_physical_attrs 100 100 2100  1000       0     0     0>
      , <&key_physical_attrs 100 100 2200  1000       0     0     0>
      , <&key_physical_attrs 100 100 2300  1000       0     0     0>
      , <&key_physical_attrs 100 100 2400  1000       0     0     0>
      , <&key_physical_attrs 100 100 2500  1000       0     0     0>
      , <&key_physical_attrs 100 100 2600  1000       0     0     0>
      , <&key_physical_attrs 100 100 2700  1000       0     0     0>
      , <&key_physical_attrs 100 100 2800  1000       0     0     0>
      , <&key_physical_attrs 100 100 2900  1000       0     0     0>
      , <&key_physical_attrs 100 100 3000  1000       0     0     0>
      , <&key_physical_attrs 100 100 3100  1000       0     0     0>
      , <&key_physical_attrs 100 100 0  1100       0     0     0>
      , <&key_physical_attrs 100 100 100  1100       0     0     0>
      , <&key_physical_attrs 100 100 200  1100       0     0     0>
      , <&key_physical_attrs 100 100 300  1100       0     0     0>
      , <&key_physical_attrs 100 100 400  1100       0     0     0>
      , <&key_physical_attrs 100 100 500  1100       0     0     0>
      , <&key_physical_attrs 100 100 600  1100       0     0     0>
      , <&key_physical_attrs 100 100 700  1100       0     0     0>
      , <&key_physical_attrs 100 100 800  1100       0     0     0>
      , <&key_physical_attrs 100 100 900  1100       0     0     0>
      , <&key_physical_attrs 100 100 1000  1100       0     0     0>
      , <&key_physical_attrs 100 100 1100  1100       0     0     0>
      , <&key_physical_attrs 100 100 1200  1100       0     0     0>
      , <&key_physical_attrs 100 100 1300  1100       0     0     0>
      , <&key_physical_attrs 100 100 1400  1100       0     0     0>
      , <&key_physical_attrs 100 100 1500  1100       0     0     0>
      , <&key_physical_attrs 100 100 1600  1100       0     0     0>
      , <&key_physical_attrs 100 100 1700  1100       0     0     0>
      , <&key_physical_attrs 100 100 1800  1100       0     0     0>
      , <&key_physical_attrs 100 100 1900  1100       0     0     0>
      , <&key_physical_attrs 100 100 2000  1100       0     0     0>
      , <&key_physical_attrs 100 100 2100  1100       0     0     0>
      , <&key_physical_attrs 100 100 2200  1100       0     0     0>
      , <&key_physical_attrs 100 100 2300  1100       0     0     0>
      , <&key_physical_attrs 100 100 2400  1100       0     0     0>
      , <&key_physical_attrs 100 100 2500  1100       0     0     0>
      , <&key_physical_attrs 100 100 2600  1100       0     0     0>
      , <&key_physical_attrs 100 100 2700  1100       0     0     0>
      , <&key_physical_attrs 100 100 2800  1100       0     0     0>
      , <&key_physical_attrs 100 100 2900  1100       0     0     0>
      , <&key_physical_attrs 100 100 3000  1100       0     0     0>
      , <&key_physical_attrs 100 100 3100  1100       0     0     0>
      , <&key_physical_attrs 100 100 0  1200       0     0     0>
      , <&key_physical_attrs 100 100 100  1200       0     0     0>
      , <&key_physical_attrs 100 100 200  1200       0     0     0>
      , <&key_physical_attrs 100 100 300  1200       0     0     0>
      , <&key_physical_attrs 100 100 400  1200       0     0     0>
      , <&key_physical_attrs 100 100 500  1200       0     0     0>
      , <&key_physical_attrs 100 100 600  1200       0     0     0>
      , <&key_physical_attrs 100 100 700  1200       0     0     0>
      , <&key_physical_attrs 100 100 800  1200       0     0     0>
      , <&key_physical_attrs 100 100 900  1200       0     0     0>
      , <&key_physical_attrs 100 100 1000  1200       0     0     0>
      , <&key_physical_attrs 100 100 1100  1200       0     0     0>
      , <&key_physical_attrs 100 100 1200  1200       0     0     0>
      , <&key_physical_attrs 100 100 1300  1200       0     0     0>
      , <&key_physical_attrs 100 100 1400  1200       0     0     0>
      , <&key_physical_attrs 100 100 1500  1200       0     0     0>
      , <&key_physical_attrs 100 100 1600  1200       0     0     0>
      , <&key_physical_attrs 100 100 1700  1200       0     0     0>
      , <&key_physical_attrs 100 100 1800  1200       0     0     0>
      , <&key_physical_attrs 100 100 1900  1200       0     0     0>
      , <&key_physical_attrs 100 100 2000  1200       0     0     0>
      , <&key_physical_attrs 100 100 2100  1200       0     0     0>
      , <&key_physical_attrs 100 100 2200  1200       0     0     0>
      , <&key_physical_attrs 100 100 2300  1200       0     0     0>
      , <&key_physical_attrs 100 100 2400  1200       0     0     0>
      , <&key_physical_attrs 100 100 2500  1200       0     0     0>
      , <&key_physical_attrs 100 100 2600  1200       0     0     0>
      , <&key_physical_attrs 100 100 2700  1200       0     0     0>
      , <&key_physical_attrs 100 100 2800  1200       0     0     0>
      , <&key_physical_attrs 100 100 2900  1200       0     0     0>
      , <&key_physical_attrs 100 100 3000  1200       0     0     0>
      , <&key_physical_attrs 100 100 3100  1200       0     0     0>
      , <&key_physical_attrs 100 100 0  1300       0     0     0>
      , <&key_physical_attrs 100 100 100  1300       0     0     0>
      , <&key_physical_attrs 100 100 200  1300       0     0     0>
      , <&key_physical_attrs 100 100 300  1300       0     0     0>
      , <&key_physical_attrs 100 100 400  1300       0     0     0>
      , <&key_physical_attrs 100 100 500  1300       0     0     0>
      , <&key_physical_attrs 100 100 600  1300       0     0     0>
      , <&key_physical_attrs 100 100 700  1300       0     0     0>
      , <&key_physical_attrs 100 100 800  1300       0     0     0>
      , <&key_physical_attrs 100 100 900  1300       0     0     0>
      , <&key_physical_attrs 100 100 1000  1300       0     0     0>
      , <&key_physical_attrs 100 100 1100  1300       0     0     0>
      , <&key_physical_attrs 100 100 1200  1300       0     0     0>
      , <&key_physical_attrs 100 100 1300  1300       0     0     0>
      , <&key_physical_attrs 100 100 1400  1300       0     0     0>
      , <&key_physical_attrs 100 100 1500  1300       0     0     0>
      , <&key_physical_attrs 100 100 1600  1300       0     0     0>
      , <&key_physical_attrs 100 100 1700  1300       0     0     0>
      , <&key_physical_attrs 100 100 1800  1300       0     0     0>
      , <&key_physical_attrs 100 100 1900  1300       0     0     0>
      , <&key_physical_attrs 100 100 2000  1300       0     0     0>
      , <&key_physical_attrs 100 100 2100  1300       0     0     0>
      , <&key_physical_attrs 100 100 2200  1300       0     0     0>
      , <&key_physical_attrs 100 100 2300  1300       0     0     0>
      , <&key_physical_attrs 100 100 2400  1300       0     0     0>
      , <&key_physical_attrs 100 100 2500  1300       0     0     0>
      , <&key_physical_attrs 100 100 2600  1300       0     0     0>
      , <&key_physical_attrs 100 100 2700  1300       0     0     0>
      , <&key_physical_attrs 100 100 2800  1300       0     0     0>
      , <&key_physical_attrs 100 100 2900  1300       0     0     0>
      , <&key_physical_attrs 100 100 3000  1300       0     0     0>
      , <&key_physical_attrs 100 100 3100  1300       0     0     0>
      , <&key_physical_attrs 100 100 0  1400       0     0     0>
      , <&key_physical_attrs 100 100 100  1400       0     0     0>
      , <&key_physical_attrs 100 100 200  1400       0     0     0>
      , <&key_physical_attrs 100 100 300  1400       0     0     0>
      , <&key_physical_attrs 100 100 400  1400       0     0     0>
      , <&key_physical_attrs 100 100 500  1400       0     0     0>
      , <&key_physical_attrs 100 100 600  1400       0     0     0>
      , <&key_physical_attrs 100 100 700  1400       0     0     0>
      , <&key_physical_attrs 100 100 800  1400       0     0     0>
      , <&key_physical_attrs 100 100 900  1400       0     0     0>
      , <&key_physical_attrs 100 100 1000  1400       0     0     0>
      , <&key_physical_attrs 100 100 1100  1400       0     0     0>
      , <&key_physical_attrs 100 100 1200  1400       0     0     0>
      , <&key_physical_attrs 100 100 1300  1400       0     0     0>
      , <&key_physical_attrs 100 100 1400  1400       0     0     0>
      , <&key_physical_attrs 100 100 1500  1400       0     0     0>
      , <&key_physical_attrs 100 100 1600  1400       0     0     0>
      , <&key_physical_attrs 100 100 1700  1400       0     0     0>
      , <&key_physical_attrs 100 100 1800  1400       0     0     0>
      , <&key_physical_attrs 100 100 1900  1400       0     0     0>
      , <&key_physical_attrs 100 100 2000  1400       0     0     0>
      , <&key_physical_attrs 100 100 2100  1400       0     0     0>
      , <&key_physical_attrs 100 100 2200  1400       0     0     0>
      , <&key_physical_attrs 100 100 2300  1400       0     0     0>
      , <&key_physical_attrs 100 100 2400  1400       0     0     0>
      , <&key_physical_attrs 100 100 2500  1400       0     0     0>
      , <&key_physical_attrs 100 100 2600  1400       0     0     0>
      , <&key_physical_attrs 100 100 2700  1400       0     0     0>
      , <&key_physical_attrs 100 100 2800  1400       0     0     0>
      , <&key_physical_attrs 100 100 2900  1400       0     0     0>
      , <&key_physical_attrs 100 100 3000  1400       0     0     0>
      , <&key_physical_attrs 100 100 3100  1400       0     0     0>
      , <&key_physical_attrs 100 100 0  1500       0     0     0>
      , <&key_physical_attrs 100 100 100  1500       0     0     0>
      , <&key_physical_attrs 100 100 200  1500       0     0     0>
      , <&key_physical_attrs 100 100 300  1500       0     0     0>
      , <&key_physical_attrs 100 100 400  1500       0     0     0>
      , <&key_physical_attrs 100 100 500  1500       0     0     0>
      , <&key_physical_attrs 100 100 600  1500       0     0     0>
      , <&key_physical_attrs 100 100 700  1500       0     0     0>
      , <&key_physical_attrs 100 100 800  1500       0     0     0>
      , <&key_physical_attrs 100 100 900  1500       0     0     0>
      , <&key_physical_attrs 100 100 1000  1500       0     0     0>
      , <&key_physical_attrs 100 100 1100  1500       0     0     0>
      , <&key_physical_attrs 100 100 1200  1500       0     0     0>
      , <&key_physical_attrs 100 100 1300  1500       0     0     0>
      , <&key_physical_attrs 100 100 1400  1500       0     0     0>
      , <&key_physical_attrs 100 100 1500  1500       0     0     0>
      , <&key_physical_attrs 100 100 1600  1500       0     0     0>
      , <&key_physical_attrs 100 100 1700  1500       0     0     0>
      , <&key_physical_attrs 100 100 1800  1500       0     0     0>
      , <&key_physical_attrs 100 100 1900  1500       0     0     0>
      , <&key_physical_attrs 100 100 2000  1500       0     0     0>
      , <&key_physical_attrs 100 100 2100  1500       0     0     0>
      , <&key_physical_attrs 100 100 2200  1500       0     0     0>
      , <&key_physical_attrs 100 100 2300  1500       0     0     0>
      , <&key_physical_attrs 100 100 2400  1500       0     0     0>
      , <&key_physical_attrs 100 100 2500  1500       0     0     0>
      , <&key_physical_attrs 100 100 2600  1500       0     0     0>
      , <&key_physical_attrs 100 100 2700  1500       0     0     0>
      , <&key_physical_attrs 100 100 2800  1500       0     0     0>
      , <&key_physical_attrs 100 100 2900  1500       0     0     0>
      , <&key_physical_attrs 100 100 3000  1500       0     0     0>
      , <&key_physical_attrs 100 100 3100  1500       0     0     0>
      , <&key_physical_attrs 100 100 0  1600       0     0     0>
      , <&key_physical_attrs 100 100 100  1600       0     0     0>
      , <&key_physical_attrs 100 100 200  1600       0     0     0>
      , <&key_physical_attrs 100 100 300  1600       0     0     0>
      , <&key_physical_attrs 100 100 400  1600       0     0     0>
      , <&key_physical_attrs 100 100 500  1600       0     0     0>
      , <&key_physical_attrs 100 100 600  1600       0     0     0>
      , <&key_physical_attrs 100 100 700  1600       0     0     0>
      , <&key_physical_attrs 100 100 800  1600       0     0     0>
      , <&key_physical_attrs 100 100 900  1600       0     0     0>
      , <&key_physical_attrs 100 100 1000  1600       0     0     0>
      , <&key_physical_attrs 100 100 1100  1600       0     0     0>
      , <&key_physical_attrs 100 100 1200  1600       0     0     0>
      , <&key_physical_attrs 100 100 1300  1600       0     0     0>
      , <&key_physical_attrs 100 100 1400  1600       0     0     0>
      , <&key_physical_attrs 100 100 1500  1600       0     0     0>
      , <&key_physical_attrs 100 100 1600  1600       0     0     0>
      , <&key_physical_attrs 100 100 1700  1600       0     0     0>
      , <&key_physical_attrs 100 100 1800  1600       0     0     0>
      , <&key_physical_attrs 100 100 1900  1600       0     0     0>
      , <&key_physical_attrs 100 100 2000  1600       0     0     0>
      , <&key_physical_attrs 100 100 2100  1600       0     0     0>
      , <&key_physical_attrs 100 100 2200  1600       0     0     0>
      , <&key_physical_attrs 100 100 2300  1600       0     0     0>
      , <&key_physical_attrs 100 100 2400  1600       0     0     0>
      , <&key_physical_attrs 100 100 2500  1600       0     0     0>
      , <&key_physical_attrs 100 100 2600  1600       0     0     0>
      , <&key_physical_attrs 100 100 2700  1600       0     0     0>
      , <&key_physical_attrs 100 100 2800  1600       0     0     0>
      , <&key_physical_attrs 100 100 2900  1600       0     0     0>
      , <&key_physical_attrs 100 100 3000  1600       0     0     0>
      , <&key_physical_attrs 100 100 3100  1600       0     0     0>
      , <&key_physical_attrs 100 100 0  1700       0     0     0>
      , <&key_physical_attrs 100 100 100  1700       0     0     0>
      , <&key_physical_attrs 100 100 200  1700       0     0     0>
      , <&key_physical_attrs 100 100 300  1700       0     0     0>
      , <&key_physical_attrs 100 100 400  1700       0     0     0>
      , <&key_physical_attrs 100 100 500  1700       0     0     0>
      , <&key_physical_attrs 100 100 600  1700       0     0     0>
      , <&key_physical_attrs 100 100 700  1700       0     0     0>
      , <&key_physical_attrs 100 100 800  1700       0     0     0>
      , <&key_physical_attrs 100 100 900  1700       0     0     0>
      , <&key_physical_attrs 100 100 1000  1700       0     0     0>
      , <&key_physical_attrs 100 100 1100  1700       0     0     0>
      , <&key_physical_attrs 100 100 1200  1700       0     0     0>
      , <&key_physical_attrs 100 100 1300  1700       0     0     0>
      , <&key_physical_attrs 100 100 1400  1700       0     0     0>
      , <&key_physical_attrs 100 100 1500  1700       0     0     0>
      , <&key_physical_attrs 100 100 1600  1700       0     0     0>
      , <&key_physical_attrs 100 100 1700  1700       0     0     0>
      , <&key_physical_attrs 100 100 1800  1700       0     0     0>
      , <&key_physical_attrs 100 100 1900  1700       0     0     0>
      , <&key_physical_attrs 100 100 2000  1700       0     0     0>
      , <&key_physical_attrs 100 100 2100  1700       0     0     0>
      , <&key_physical_attrs 100 100 2200  1700       0     0     0>
      , <&key_physical_attrs 100 100 2300  1700       0     0     0>
      , <&key_physical_attrs 100 100 2400  1700       0     0     0>
      , <&key_physical_attrs 100 100 2500  1700       0     0     0>
      , <&key_physical_attrs 100 100 2600  1700       0     0     0>
      , <&key_physical_attrs 100 100 2700  1700       0     0     0>
      , <&key_physical_attrs 100 100 2800  1700       0     0     0>
      , <&key_physical_attrs 100 100 2900  1700       0     0     0>
      , <&key_physical_attrs 100 100 3000  1700       0     0     0>
      , <&key_physical_attrs 100 100 3100  1700       0     0     0>
      , <&key_physical_attrs 100 100 0  1800       0     0     0>
      , <&key_physical_attrs 100 100 100  1800       0     0     0>
      , <&key_physical_attrs 100 100 200  1800       0     0     0>
      , <&key_physical_attrs 100 100 300  1800       0     0     0>
      , <&key_physical_attrs 100 100 400  1800       0     0     0>
      , <&key_physical_attrs 100 100 500  1800       0     0     0>
      , <&key_physical_attrs 100 100 600  1800       0     0     0>
      , <&key_physical_attrs 100 100 700  1800       0     0     0>
      , <&key_physical_attrs 100 100 800  1800       0     0     0>
      , <&key_physical_attrs 100 100 900  1800       0     0     0>
      , <&key_physical_attrs 100 100 1000  1800       0     0     0>
      , <&key_physical_attrs 100 100 1100  1800       0     0     0>
      , <&key_physical_attrs 100 100 1200  1800       0     0     0>
      , <&key_physical_attrs 100 100 1300  1800       0     0     0>
      , <&key_physical_attrs 100 100 1400  1800       0     0     0>
      , <&key_physical_attrs 100 100 1500  1800       0     0     0>
      , <&key_physical_attrs 100 100 1600  1800       0     0     0>
      , <&key_physical_attrs 100 100 1700  1800       0     0     0>
      , <&key_physical_attrs 100 100 1800  1800       0     0     0>
      , <&key_physical_attrs 100 100 1900  1800       0     0     0>
      , <&key_physical_attrs 100 100 2000  1800       0     0     0>
      , <&key_physical_attrs 100 100 2100  1800       0     0     0>
      , <&key_physical_attrs 100 100 2200  1800       0     0     0>
      , <&key_physical_attrs 100 100 2300  1800       0     0     0>
      , <&key_physical_attrs 100 100 2400  1800       0     0     0>
      , <&key_physical_attrs 100 100 2500  1800       0     0     0>
      , <&key_physical_attrs 100 100 2600  1800       0     0     0>
      , <&key_physical_attrs 100 100 2700  1800       0     0     0>
      , <&key_physical_attrs 100 100 2800  1800       0     0     0>
      , <&key_physical_attrs 100 100 2900  1800       0     0     0>
      , <&key_physical_attrs 100 100 3000  1800       0     0     0>
      , <&key_physical_attrs 100 100 3100  1800       0     0     0>
      , <&key_physical_attrs 100 100 0  1900       0     0     0>
      , <&key_physical_attrs 100 100 100  1900       0     0     0>
      , <&key_physical_attrs 100 100 200  1900       0     0     0>
      , <&key_physical_attrs 100 100 300  1900       0     0     0>
      , <&key_physical_attrs 100 100 400  1900       0     0     0>
      , <&key_physical_attrs 100 100 500  1900       0     0     0>
      , <&key_physical_attrs 100 100 600  1900       0     0     0>
      , <&key_physical_attrs 100 100 700  1900       0     0     0>
      , <&key_physical_attrs 100 100 800  1900       0     0     0>
      , <&key_physical_attrs 100 100 900  1900       0     0     0>
      , <&key_physical_attrs 100 100 1000  1900       0     0     0>
      , <&key_physical_attrs 100 100 1100  1900       0     0     0>
      , <&key_physical_attrs 100 100 1200  1900       0     0     0>
      , <&key_physical_attrs 100 100 1300  1900       0     0     0>
      , <&key_physical_attrs 100 100 1400  1900       0     0     0>
      , <&key_physical_attrs 100 100 1500  1900       0     0     0>
      , <&key_physical_attrs 100 100 1600  1900       0     0     0>
      , <&key_physical_attrs 100 100 1700  1900       0     0     0>
      , <&key_physical_attrs 100 100 1800  1900       0     0     0>
      , <&key_physical_attrs 100 100 1900  1900       0     0     0>
      , <&key_physical_attrs 100 100 2000  1900       0     0     0>
      , <&key_physical_attrs 100 100 2100  1900       0     0     0>
      , <&key_physical_attrs 100 100 2200  1900       0     0     0>
      , <&key_physical_attrs 100 100 2300  1900       0     0     0>
      , <&key_physical_attrs 100 100 2400  1900       0     0     0>
      , <&key_physical_attrs 100 100 2500  1900       0     0     0>
      , <&key_physical_attrs 100 100 2600  1900       0     0     0>
      , <&key_physical_attrs 100 100 2700  1900       0     0     0>
      , <&key_physical_attrs 100 100 2800  1900       0     0     0>
      , <&key_physical_attrs 100 100 2900  1900       0     0     0>
      , <&key_physical_attrs 100 100 3000  1900       0     0     0>
      , <&key_physical_attrs 100 100 3100  1900       0     0     0>
            ;
    };
    position_map {
        compatible = "zmk,physical-layout-position-map";

        complete;

        layout_0 {
            physical-layout = <&layout_0>;
            positions
                = < 0  1  2  3  4  5  6  7  8  9 10 11 12 13 14 15>
                , <16 17 18 19 20 21 22 23 24 25 26 27 28 29 30 31>
                , <32 33 34 35 36 37 38 39 40 41 42 43 44 45 46 47>
                , <48 49 50 51 52 53 54 55 56 57 58 59 60 85 61 62>
                , <63 64 65 66 67 68 69 70 71 72 73 74 75 76 77 78>
                , <79 80 81 82 83 84 86 87 88 89 90 91 92 93 94 95>
                , <96 97 98 99 100 101 102 103 104 105 106 107 108>
                , <109 110 111 112 113 114 115 116 117 118 119 120>
                , <121 122 123 124 125 126 127 128 129 130 131 132>
                , <133 134 135 136 137 138 139 140 141 142 143 144>
                , <145 146 147 148 149 150 151 152 153 154 155 156>
                , <157 158 159 160 161 162 163 164 165 166 167 168>
                , <169 170 171 172 173 174 175 176 177 178 179 180>
                , <181 182 183 184 185 186 187 188 189 190 191 192>
                , <193 194 195 196 197 198 199 200 201 202 203 204> 
                , <205 206 207 208 209 210 211 212 213 214 215 216> 
                , <217 218 219 220 221 222 223 224 225 226 227 228> 
                , <229 230 231 232 233 234 235 236 237 238 239 240> 
                , <241 242 243 244 245 246 247 248 249 250 251 252> 
                , <253 254 255 256 257 258 259 260 261 262 263 264> 
                , <265 266 267 268 269 270 271 272 273 274 275 276> 
                , <277 278 279 280 281 282 283 284 285 286 287 288> 
                , <289 290 291 292 293 294 295 296 297 298 299 300> 
                , <301 302 303 304 305 306 307 308 309 310 311 312> 
                , <313 314 315 316 317 318 319 320 321 322 323 324> 
                , <325 326 327 328 329 330 331 332 333 334 335 336> 
                , <337 338 339 340 341 342 343 344 345 346 347 348> 
                , <349 350 351 352 353 354 355 356 357 358 359 360> 
                , <361 362 363 364 365 366 367 368 369 370 371 372> 
                , <373 374 375 376 377 378 379 380 381 382 383 384> 
                , <385 386 387 388 389 390 391 392 393 394 395 396> 
                , <397 398 399 400 401 402 403 404 405 406 407 408> 
                , <409 410 411 412 413 414 415 416 417 418 419 420> 
                , <421 422 423 424 425 426 427 428 429 430 431 432> 
                , <433 434 435 436 437 438 439 440 441 442 443 444> 
                , <445 446 447 448 449 450 451 452 453 454 455 456> 
                , <457 458 459 460 461 462 463 464 465 466 467 468 469 >
                ;
        };

        layout_1 {
            physical-layout = <&layout_1>;
            positions
                = < 0  1  2  3  4  5  6  7  8  9 10 11 12 13 14 15>
                , <16 17 18 19 20 21 22 23 24 25 26 27 28 29 30 31>
                , <32 33 34 35 36 37 38 39 40 41 42 43 57 44 45 46>
                , <47 48 49 50 51 52 53 54 55 56 58 59 60 61 62 63>
                , <64 65 66 67 68 69 70 71 72 73 74 75 76 77 78 79>
                , <80 81 82 83 84 85 86 87 88 89 90 91 92 93 94 95>
                , <96 97 98 99 100 101 102 103 104 105 106 107 108>
                , <109 110 111 112 113 114 115 116 117 118 119 120>
                , <121 122 123 124 125 126 127 128 129 130 131 132>
                , <133 134 135 136 137 138 139 140 141 142 143 144>
                , <145 146 147 148 149 150 151 152 153 154 155 156>
                , <157 158 159 160 161 162 163 164 165 166 167 168>
                , <169 170 171 172 173 174 175 176 177 178 179 180>
                , <181 182 183 184 185 186 187 188 189 190 191 192>
                , <193 194 195 196 197 198 199 200 201 202 203 204> 
                , <205 206 207 208 209 210 211 212 213 214 215 216> 
                , <217 218 219 220 221 222 223 224 225 226 227 228> 
                , <229 230 231 232 233 234 235 236 237 238 239 240> 
                , <241 242 243 244 245 246 247 248 249 250 251 252> 
                , <253 254 255 256 257 258 259 260 261 262 263 264> 
                , <265 266 267 268 269 270 271 272 273 274 275 276> 
                , <277 278 279 280 281 282 283 284 285 286 287 288> 
                , <289 290 291 292 293 294 295 296 297 298 299 300> 
                , <301 302 303 304 305 306 307 308 309 310 311 312> 
                , <313 314 315 316 317 318 319 320 321 322 323 324> 
                , <325 326 327 328 329 330 331 332 333 334 335 336> 
                , <337 338 339 340 341 342 343 344 345 346 347 348> 
                , <349 350 351 352 353 354 355 356 357 358 359 360> 
                , <361 362 363 364 365 366 367 368 369 370 371 372> 
                , <373 374 375 376 377 378 379 380 381 382 383 384> 
                , <385 386 387 388 389 390 391 392 393 394 395 396> 
                , <397 398 399 400 401 402 403 404 405 406 407 408> 
                , <409 410 411 412 413 414 415 416 417 418 419 420> 
                , <421 422 423 424 425 426 427 428 429 430 431 432> 
                , <433 434 435 436 437 438 439 440 441 442 443 444> 
                , <445 446 447 448 449 450 451 452 453 454 455 456> 
                , <457 458 459 460 461 462 463 464 465 466 467 468 469 >
                ;
        };
    };
 };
